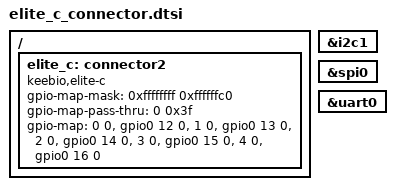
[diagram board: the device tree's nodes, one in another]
/*
 * Copyright (c) 2020 Pete Johanson
 * Copyright (c) 2024 burkfers
 * Copyright (c) 2024 Charly Delay <0@0xcharly.com>
 *
 * SPDX-License-Identifier: MIT
 */

/ {
	elite_c: connector2 {
		compatible = "keebio,elite-c";
		#gpio-cells = <2>;
		gpio-map-mask = <0xffffffff 0xffffffc0>;
		gpio-map-pass-thru = <0 0x3f>;
		gpio-map
			= <0 0 &gpio0 12 0>	/* D12 */
			, <1 0 &gpio0 13 0>	/* D13 */
			, <2 0 &gpio0 14 0>	/* D14 */
			, <3 0 &gpio0 15 0>	/* D15 */
			, <4 0 &gpio0 16 0>	/* D16 */
			;
	};

};

elite_c_i2c: &i2c1 {};
elite_c_spi: &spi0 {};
elite_c_serial: &uart0 {};
